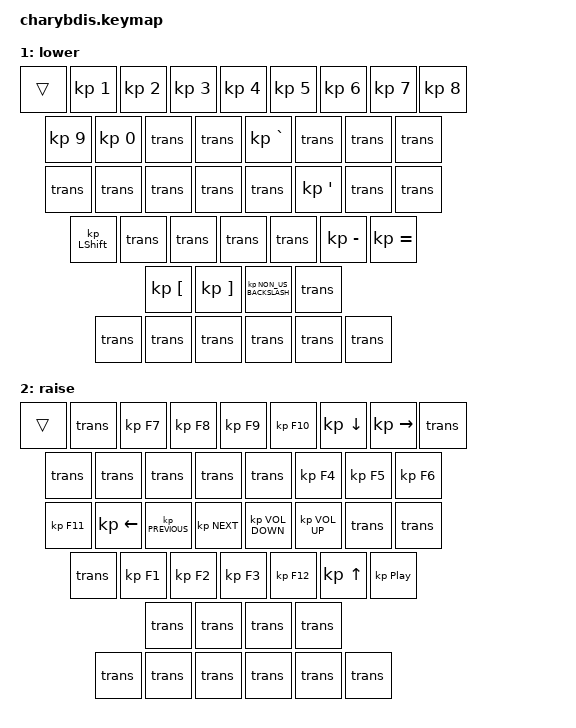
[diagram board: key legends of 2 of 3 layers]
#include <behaviors.dtsi>
#include <dt-bindings/zmk/keys.h>

/ {
  keymap {
    compatible = "zmk,keymap";

    Base {
      label = "Base";
      bindings = <&trans & kp Q & kp W & kp E & kp R & kp T & kp Y & kp U &
                  kp I & kp O & kp P & trans & trans & kp A & kp S & kp D &
                  kp F & kp G & kp H & kp J & kp K & kp L & kp SEMI & trans &
                  trans & mt LEFT_SHIFT Z & kp X & kp C & kp V & kp B & kp N &
                  kp M & kp COMMA & kp DOT & mt RIGHT_SHIFT FSLH & trans &
                  mt LEFT_ALT ESCAPE & kp LEFT_WIN & mt LEFT_CONTROL TAB &
                  kp RET & lt 1 SPACE & lt 2 BACKSPACE>;
    };

    lower {
      bindings =
          <&trans & kp N1 & kp N2 & kp N3 & kp N4 & kp N5 & kp N6 & kp N7 &
           kp N8 & kp N9 & kp N0 & trans & trans & kp GRAVE & trans & trans &
           trans & trans & trans & trans & trans & trans & kp SQT & trans &
           trans & kp LEFT_SHIFT & trans & trans & trans & trans & kp MINUS &
           kp EQUAL & kp LEFT_BRACKET & kp RIGHT_BRACKET & kp NON_US_BACKSLASH &
           trans & trans & trans & trans & trans & trans & trans>;
    };

    raise {
      bindings =
          <&trans & trans & kp F7 & kp F8 & kp F9 & kp F10 & kp DOWN &
           kp RIGHT & trans & trans & trans & trans & trans & trans & kp F4 &
           kp F5 & kp F6 & kp F11 & kp LEFT & kp C_PREVIOUS & kp C_NEXT &
           kp C_VOLUME_DOWN & kp C_VOLUME_UP & trans & trans & trans & kp F1 &
           kp F2 & kp F3 & kp F12 & kp UP & kp C_PLAY_PAUSE & trans & trans &
           trans & trans & trans & trans & trans & trans & trans & trans>;
    };
  };
};
